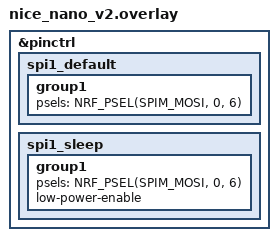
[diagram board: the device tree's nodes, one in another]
&pinctrl {
	spi1_default: spi1_default {
		group1 {
			psels = <NRF_PSEL(SPIM_MOSI, 0, 6)>;
		};
	};

	spi1_sleep: spi1_sleep {
		group1 {
			psels = <NRF_PSEL(SPIM_MOSI, 0, 6)>;
			low-power-enable;
		};
	};
};
